# G32F031 register map
File version: 1.0
CPU: CM0PLUS r0p1, little endian, no MPU, no FPU, 2 interrupt priority bits
Registers are 32-bit, read-write, reset 0x0 unless marked. A register's access mark holds for its fields unless they carry their own. Offsets are from the block's base; [hi:lo] are bit positions; {n}, {i} and the like mark numbered series.

## GPIOA — General-purpose I/Os
Base 0x48000000
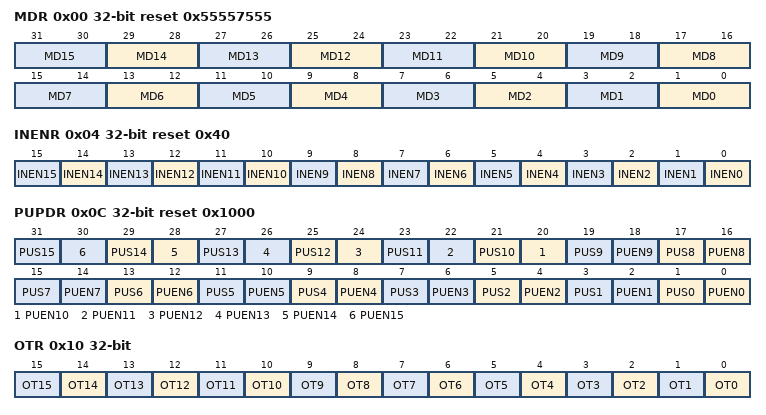
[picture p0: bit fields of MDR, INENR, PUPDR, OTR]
0x00 MDR reset 0x55557555
  [2n+1:2n] MD{n} (n=0..15) — /
0x04 INENR reset 0x40
  [n] INEN{n} (n=0..15) — /
0x0C PUPDR reset 0x1000
  [2n+1] PUS{n} (n=0..15) — /
  [2n] PUEN{n} (n=0..15) — /
0x10 OTR
  [n] OT{n} (n=0..15) — /
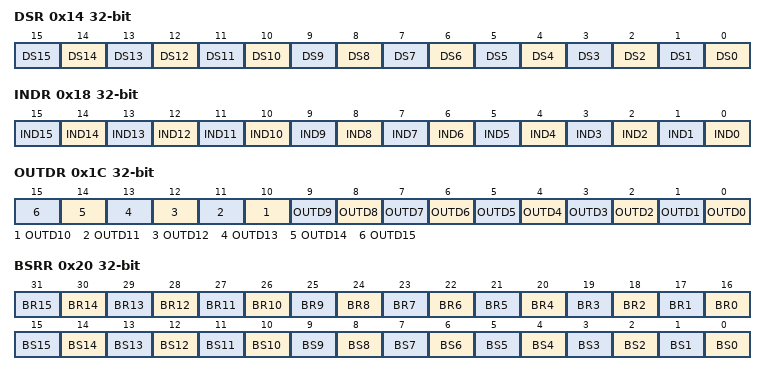
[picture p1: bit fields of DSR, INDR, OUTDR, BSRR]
0x14 DSR
  [n] DS{n} (n=0..15) — /
0x18 INDR ro
  [n] IND{n} (n=0..15) — /
0x1C OUTDR
  [n] OUTD{n} (n=0..15) — /
0x20 BSRR
  [n+16] BR{n} (n=0..15) — /
  [n] BS{n} (n=0..15) — /
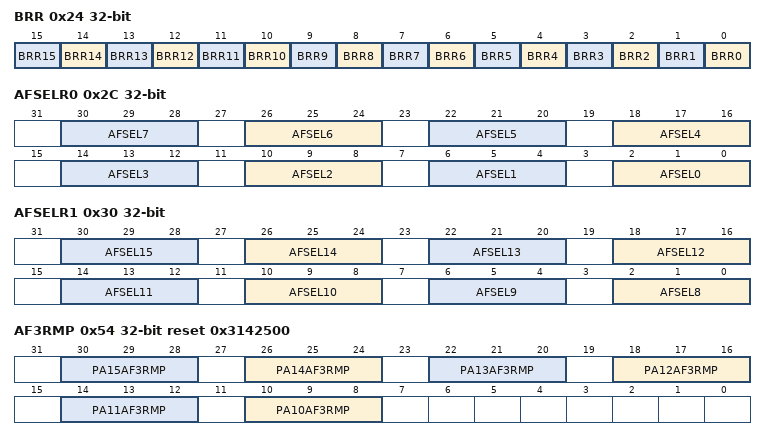
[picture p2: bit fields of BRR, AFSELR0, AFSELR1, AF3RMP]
0x24 BRR
  [n] BRR{n} (n=0..15) — /
0x28 LOCK
  [31:0] KEY — /
0x2C AFSELR0
  [4n+2:4n] AFSEL{n} (n=0..7) — /
0x30 AFSELR1
  [4n-30:4n-32] AFSEL{n} (n=8..15) — /
0x54 AF3RMP reset 0x3142500
  [4n-30:4n-32] PA{n}AF3RMP (n=10..15) — /

## GPIOB — General-purpose I/Os
Base 0x48000400
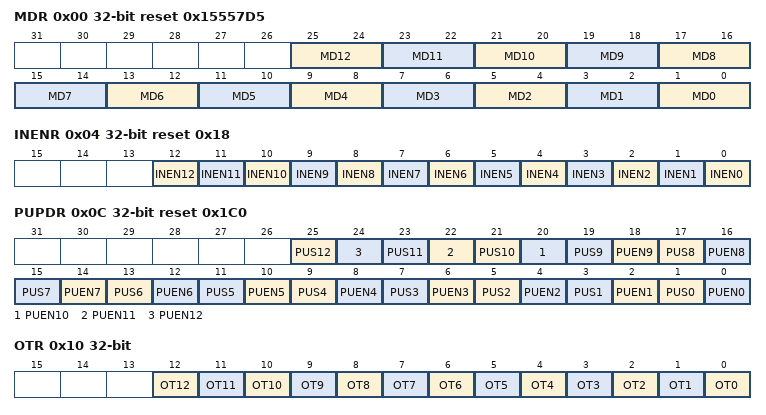
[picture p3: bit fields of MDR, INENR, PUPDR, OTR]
0x00 MDR reset 0x15557D5
  [2n+1:2n] MD{n} (n=0..12) — /
0x04 INENR reset 0x18
  [n] INEN{n} (n=0..12) — /
0x0C PUPDR reset 0x1C0
  [2n+1] PUS{n} (n=0..12) — /
  [2n] PUEN{n} (n=0..12) — /
0x10 OTR
  [n] OT{n} (n=0..12) — /
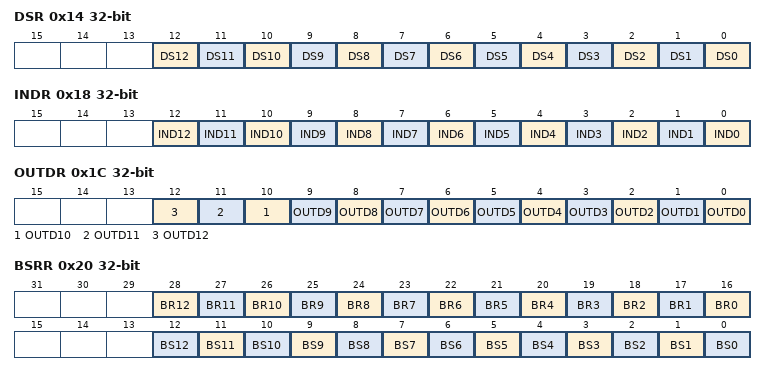
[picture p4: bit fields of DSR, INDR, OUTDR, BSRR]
0x14 DSR
  [n] DS{n} (n=0..12) — /
0x18 INDR
  [n] IND{n} (n=0..12) — /
0x1C OUTDR
  [n] OUTD{n} (n=0..12) — /
0x20 BSRR
  [n+16] BR{n} (n=0..12) — /
  [n] BS{n} (n=0..12) — /
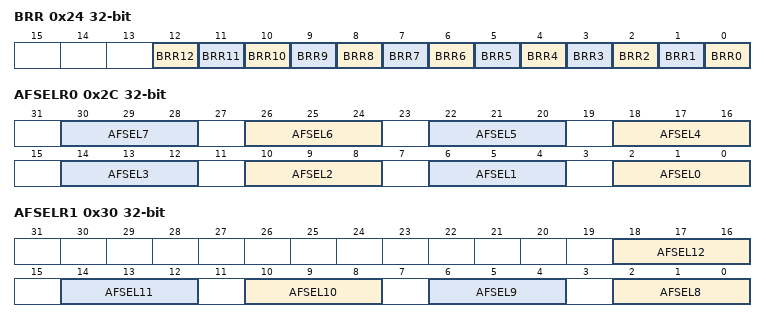
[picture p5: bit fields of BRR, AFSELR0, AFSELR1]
0x24 BRR
  [n] BRR{n} (n=0..12) — /
0x28 LOCK
  [31:0] KEY — /
0x2C AFSELR0
  [4n+2:4n] AFSEL{n} (n=0..7) — /
0x30 AFSELR1
  [4n-30:4n-32] AFSEL{n} (n=8..12) — /

## I2C — Inter-Integrated Circuit
Base 0x40004400
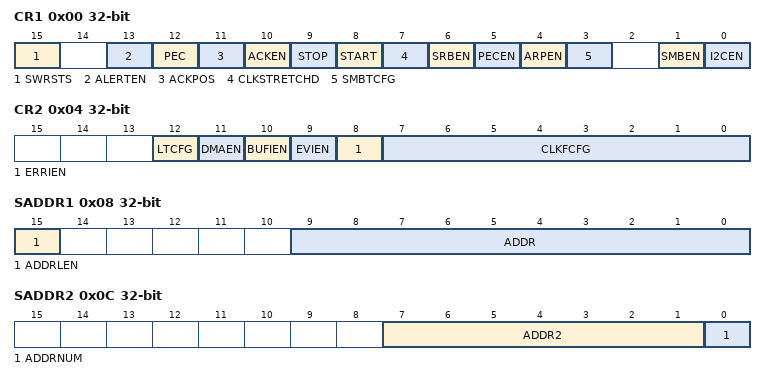
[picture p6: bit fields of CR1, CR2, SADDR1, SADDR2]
0x00 CR1 — control register 1
  [15] SWRSTS — Software Configure I2C under Reset State
  [13] ALERTEN — SMBus Alert Enable
  [12] PEC — Packet Error Check Transfer Enable
  [11] ACKPOS — Acknowledge /PEC Position Configure
  [10] ACKEN — Acknowledge Transfer Enable
  [9] STOP — Stop Bit Transfer
  [8] START — Start Bit Transfer
  [7] CLKSTRETCHD — Slave Mode Clock Stretching Disable
  [6] SRBEN — Slave Responds Broadcast Enable
  [5] PECEN — PEC Enable
  [4] ARPEN — ARP Enable
  [3] SMBTCFG — SMBus Type Configure
  [1] SMBEN — SMBus Mode Enable
  [0] I2CEN — I2C Enable
0x04 CR2 — control register 2
  [12] LTCFG — DMA Last Transfer Configure
  [11] DMAEN — DMA Requests Enable
  [10] BUFIEN — Error interrupt enable
  [9] EVIEN — Event Interrupt Enable
  [8] ERRIEN — Error Interrupt Enable
  [7:0] CLKFCFG — I2C Clock Frequency Configure
0x08 SADDR1 — Slave Mode Address Register 1
  [15] ADDRLEN — Slave Address Length Configure
  [9:0] ADDR — Slave Address Setup
0x0C SADDR2 — Slave Mode Address Register 2
  [7:1] ADDR2 — Slave Dual Address Mode Address Setup
  [0] ADDRNUM — Slave Address Number Configure
0x10 DR — data register
  [7:0] DATA
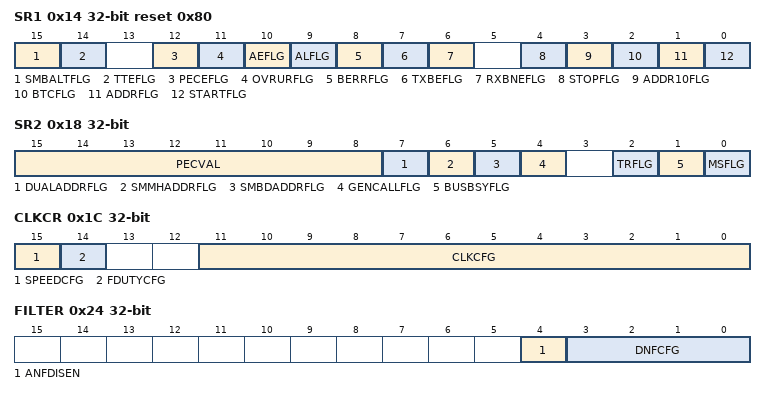
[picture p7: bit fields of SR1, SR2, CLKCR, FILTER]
0x14 SR1 access per field reset 0x80 — Status register 1
  [15] SMBALTFLG rw — SMBus Alert Occur Flag
  [14] TTEFLG rw — Timeout or Tlow Error Flag
  [12] PECEFLG rw — PEC Error in Reception Flag
  [11] OVRURFLG rw — Overrun/Underrun Flag
  [10] AEFLG rw — Acknowledge Error Flag
  [9] ALFLG rw — Master Mode Arbitration Lost Flag
  [8] BERRFLG rw — Bus Error Flag
  [7] TXBEFLG ro — Transmit Buffer Empty Flag
  [6] RXBNEFLG ro — Receive Buffer Not Empty Flag
  [4] STOPFLG ro — Stop Bit Detection Flag
  [3] ADDR10FLG ro — 10-Bit Address Header Transmit Flag
  [2] BTCFLG ro — Byte Transfer Complete Flag
  [1] ADDRFLG ro — Address Transfer Complete / Receive Match Flag
  [0] STARTFLG ro — Start Bit Sent Finished Flag
0x18 SR2 ro — Status register 2
  [15:8] PECVAL — Save Packet Error Checking Value
  [7] DUALADDRFLG — Slave Mode Received Dual Address Match Flag
  [6] SMMHADDRFLG — SMBus Device Received Master Header Flag in Slave Mode
  [5] SMBDADDRFLG — SMBus Device Received Default Address Flag in Slave Mode
  [4] GENCALLFLG — Slave Mode Received General Call Address Flag
  [2] TRFLG — Transmitter / Receiver Mode Flag
  [1] BUSBSYFLG — Bus Busy Flag
  [0] MSFLG — Master Slave Mode Flag
0x1C CLKCR — Host Clock Control Register
  [15] SPEEDCFG — Master Mode Speed Configure
  [14] FDUTYCFG — Fast Mode Duty Cycle Configure
  [11:0] CLKCFG — Clock Setup in Fast/Standard Master Mode
0x20 RISETMAX reset 0x2 — Maximum Rise Time Register
  [7:0] RISETMAX — Master Mode Maximum Rise Time in Fast/Standard Mode
0x24 FILTER — Filter Control Register
  [4] ANFDISEN — Analog Noise Filter Disable
  [3:0] DNFCFG — Digital Noise Filter Filtering Capability Configure
